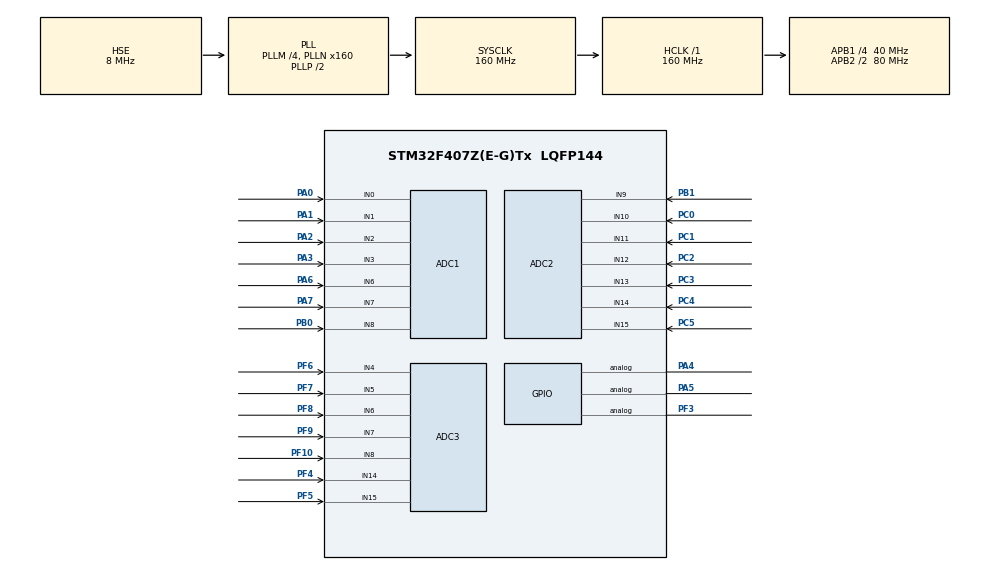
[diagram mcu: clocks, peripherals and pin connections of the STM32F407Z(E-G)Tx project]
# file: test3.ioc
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ADC1.Channel-0\#ChannelRegularConversion=ADC_CHANNEL_0
ADC1.NbrOfConversionFlag=1
ADC1.Rank-0\#ChannelRegularConversion=1
ADC1.SamplingTime-0\#ChannelRegularConversion=ADC_SAMPLETIME_3CYCLES
ADC1.master=1
ADC2.Channel-0\#ChannelRegularConversion=ADC_CHANNEL_9
ADC2.NbrOfConversionFlag=1
ADC2.Rank-0\#ChannelRegularConversion=1
ADC2.SamplingTime-0\#ChannelRegularConversion=ADC_SAMPLETIME_3CYCLES
ADC3.Channel-0\#ChannelRegularConversion=ADC_CHANNEL_4
ADC3.NbrOfConversionFlag=1
ADC3.Rank-0\#ChannelRegularConversion=1
ADC3.SamplingTime-0\#ChannelRegularConversion=ADC_SAMPLETIME_3CYCLES
FREERTOS.Tasks01=defaultTask,0,512,StartDefaultTask,Default,NULL,Dynamic,NULL,NULL
FREERTOS.configENABLE_BACKWARD_COMPATIBILITY=0
FREERTOS.configUSE_IDLE_HOOK=1
Mcu.Family=STM32F4
Mcu.Name=STM32F407Z(E-G)Tx
Mcu.Package=LQFP144
NVIC.PriorityGroup=NVIC_PRIORITYGROUP_4
NVIC.TIM6_DAC_IRQn=true\:0\:0\:false\:false\:true\:false\:false\:true
NVIC.TimeBase=TIM6_DAC_IRQn
NVIC.TimeBaseIP=TIM6
PA0-WKUP.Signal=ADCx_IN0
PA1.Signal=ADCx_IN1
PA13.Mode=Serial_Wire
PA13.Signal=SYS_JTMS-SWDIO
PA14.Mode=Serial_Wire
PA14.Signal=SYS_JTCK-SWCLK
PA2.Signal=ADCx_IN2
PA3.Signal=ADCx_IN3
PA4.Signal=GPIO_Analog
PA5.Signal=GPIO_Analog
PA6.Signal=ADCx_IN6
PA7.Signal=ADCx_IN7
PB0.Signal=ADCx_IN8
PB1.Signal=ADCx_IN9
PC0.Signal=ADCx_IN10
PC1.Signal=ADCx_IN11
PC14-OSC32_IN.Mode=LSE-External-Oscillator
PC14-OSC32_IN.Signal=RCC_OSC32_IN
PC15-OSC32_OUT.Mode=LSE-External-Oscillator
PC15-OSC32_OUT.Signal=RCC_OSC32_OUT
PC2.Signal=ADCx_IN12
PC3.Signal=ADCx_IN13
PC4.Signal=ADCx_IN14
PC5.Signal=ADCx_IN15
PF10.Mode=IN8
PF10.Signal=ADC3_IN8
PF3.Signal=GPIO_Analog
PF4.Mode=IN14
PF4.Signal=ADC3_IN14
PF5.Mode=IN15
PF5.Signal=ADC3_IN15
PF6.Mode=IN4
PF6.Signal=ADC3_IN4
PF7.Mode=IN5
PF7.Signal=ADC3_IN5
PF8.Mode=IN6
PF8.Signal=ADC3_IN6
PF9.Mode=IN7
PF9.Signal=ADC3_IN7
PH0-OSC_IN.Mode=HSE-External-Oscillator
PH0-OSC_IN.Signal=RCC_OSC_IN
PH1-OSC_OUT.Mode=HSE-External-Oscillator
PH1-OSC_OUT.Signal=RCC_OSC_OUT
ProjectManager.HeapSize=0x200
ProjectManager.StackSize=0x400
ProjectManager.TargetToolchain=Makefile
RCC.48MHZClocksFreq_Value=45714285.71428572
RCC.AHBFreq_Value=160000000
RCC.APB1CLKDivider=RCC_HCLK_DIV4
RCC.APB1Freq_Value=40000000
RCC.APB1TimFreq_Value=80000000
RCC.APB2CLKDivider=RCC_HCLK_DIV2
RCC.APB2Freq_Value=80000000
RCC.APB2TimFreq_Value=160000000
RCC.CortexFreq_Value=160000000
RCC.HCLKFreq_Value=160000000
RCC.HSE_VALUE=8000000
RCC.HSI_VALUE=16000000
RCC.PLLM=4
RCC.PLLN=160
RCC.PLLQ=7
RCC.PLLSourceVirtual=RCC_PLLSOURCE_HSE
RCC.RCC_RTC_Clock_Source=RCC_RTCCLKSOURCE_LSE
RCC.RCC_RTC_Clock_SourceVirtual=RCC_RTCCLKSOURCE_LSE
RCC.SYSCLKFreq_VALUE=160000000
RCC.SYSCLKSource=RCC_SYSCLKSOURCE_PLLCLK
RCC.VCOOutputFreq_Value=320000000
SH.ADCx_IN0.0=ADC1_IN0,IN0
SH.ADCx_IN1.0=ADC1_IN1,IN1
SH.ADCx_IN10.0=ADC2_IN10,IN10
SH.ADCx_IN11.0=ADC2_IN11,IN11
SH.ADCx_IN12.0=ADC2_IN12,IN12
SH.ADCx_IN13.0=ADC2_IN13,IN13
SH.ADCx_IN14.0=ADC2_IN14,IN14
SH.ADCx_IN15.0=ADC2_IN15,IN15
SH.ADCx_IN2.0=ADC1_IN2,IN2
SH.ADCx_IN3.0=ADC1_IN3,IN3
SH.ADCx_IN6.0=ADC1_IN6,IN6
SH.ADCx_IN7.0=ADC1_IN7,IN7
SH.ADCx_IN8.0=ADC1_IN8,IN8
SH.ADCx_IN9.0=ADC2_IN9,IN9
VP_FREERTOS_VS_CMSIS_V1.Mode=CMSIS_V1
VP_RTC_VS_RTC_Activate.Mode=RTC_Enabled
VP_SYS_VS_tim6.Mode=TIM6
board=custom

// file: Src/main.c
/* USER CODE BEGIN Header */
/**
  ******************************************************************************
  * @file           : main.c
  * @brief          : Main program body
  ******************************************************************************
  ** This notice applies to any and all portions of this file
  * that are not between comment pairs USER CODE BEGIN and
  * USER CODE END. Other portions of this file, whether
  * inserted by the user or by software development tools
  * are owned by their respective copyright owners.
  *
  * COPYRIGHT(c) 2018 STMicroelectronics
  *
  * Redistribution and use in source and binary forms, with or without modification,
  * are permitted provided that the following conditions are met:
  *   1. Redistributions of source code must retain the above copyright notice,
  *      this list of conditions and the following disclaimer.
  *   2. Redistributions in binary form must reproduce the above copyright notice,
  *      this list of conditions and the following disclaimer in the documentation
  *      and/or other materials provided with the distribution.
  *   3. Neither the name of STMicroelectronics nor the names of its contributors
  *      may be used to endorse or promote products derived from this software
  *      without specific prior written permission.
  *
  * THIS SOFTWARE IS PROVIDED BY THE COPYRIGHT HOLDERS AND CONTRIBUTORS "AS IS"
  * AND ANY EXPRESS OR IMPLIED WARRANTIES, INCLUDING, BUT NOT LIMITED TO, THE
  * IMPLIED WARRANTIES OF MERCHANTABILITY AND FITNESS FOR A PARTICULAR PURPOSE ARE
  * DISCLAIMED. IN NO EVENT SHALL THE COPYRIGHT HOLDER OR CONTRIBUTORS BE LIABLE
  * FOR ANY DIRECT, INDIRECT, INCIDENTAL, SPECIAL, EXEMPLARY, OR CONSEQUENTIAL
  * DAMAGES (INCLUDING, BUT NOT LIMITED TO, PROCUREMENT OF SUBSTITUTE GOODS OR
  * SERVICES; LOSS OF USE, DATA, OR PROFITS; OR BUSINESS INTERRUPTION) HOWEVER
  * CAUSED AND ON ANY THEORY OF LIABILITY, WHETHER IN CONTRACT, STRICT LIABILITY,
  * OR TORT (INCLUDING NEGLIGENCE OR OTHERWISE) ARISING IN ANY WAY OUT OF THE USE
  * OF THIS SOFTWARE, EVEN IF ADVISED OF THE POSSIBILITY OF SUCH DAMAGE.
  *
  ******************************************************************************
  */
/* USER CODE END Header */

#include "main.h"
#include "cmsis_os.h"

ADC_HandleTypeDef hadc1;
ADC_HandleTypeDef hadc2;
ADC_HandleTypeDef hadc3;

RTC_HandleTypeDef hrtc;

osThreadId defaultTaskHandle;

void SystemClock_Config(void);
static void MX_GPIO_Init(void);
static void MX_RTC_Init(void);
static void MX_ADC3_Init(void);
static void MX_ADC1_Init(void);
static void MX_ADC2_Init(void);
void StartDefaultTask(void const * argument);

int main(void)
{

  /* MCU Configuration--------------------------------------------------------*/

  /* Reset of all peripherals, Initializes the Flash interface and the Systick. */
  HAL_Init();

  /* Configure the system clock */
  SystemClock_Config();

  /* Initialize all configured peripherals */
  MX_GPIO_Init();
  MX_RTC_Init();
  MX_ADC3_Init();
  MX_ADC1_Init();
  MX_ADC2_Init();

  /* Create the thread(s) */
  /* definition and creation of defaultTask */
  osThreadDef(defaultTask, StartDefaultTask, osPriorityNormal, 0, 512);
  defaultTaskHandle = osThreadCreate(osThread(defaultTask), NULL);

  /* Start scheduler */
  osKernelStart();

  /* We should never get here as control is now taken by the scheduler */

  /* Infinite loop */
  while (1)
  {

  }
}

void SystemClock_Config(void)
{
  RCC_OscInitTypeDef RCC_OscInitStruct = {0};
  RCC_ClkInitTypeDef RCC_ClkInitStruct = {0};
  RCC_PeriphCLKInitTypeDef PeriphClkInitStruct = {0};

  /** Configure the main internal regulator output voltage
  */
  __HAL_RCC_PWR_CLK_ENABLE();
  __HAL_PWR_VOLTAGESCALING_CONFIG(PWR_REGULATOR_VOLTAGE_SCALE1);
  /** Initializes the CPU, AHB and APB busses clocks
  */
  RCC_OscInitStruct.OscillatorType = RCC_OSCILLATORTYPE_HSE|RCC_OSCILLATORTYPE_LSE;
  RCC_OscInitStruct.HSEState = RCC_HSE_ON;
  RCC_OscInitStruct.LSEState = RCC_LSE_ON;
  RCC_OscInitStruct.PLL.PLLState = RCC_PLL_ON;
  RCC_OscInitStruct.PLL.PLLSource = RCC_PLLSOURCE_HSE;
  RCC_OscInitStruct.PLL.PLLM = 4;
  RCC_OscInitStruct.PLL.PLLN = 160;
  RCC_OscInitStruct.PLL.PLLP = RCC_PLLP_DIV2;
  RCC_OscInitStruct.PLL.PLLQ = 7;
  if (HAL_RCC_OscConfig(&RCC_OscInitStruct) != HAL_OK)
  {
    Error_Handler();
  }
  /** Initializes the CPU, AHB and APB busses clocks
  */
  RCC_ClkInitStruct.ClockType = RCC_CLOCKTYPE_HCLK|RCC_CLOCKTYPE_SYSCLK
                              |RCC_CLOCKTYPE_PCLK1|RCC_CLOCKTYPE_PCLK2;
  RCC_ClkInitStruct.SYSCLKSource = RCC_SYSCLKSOURCE_PLLCLK;
  RCC_ClkInitStruct.AHBCLKDivider = RCC_SYSCLK_DIV1;
  RCC_ClkInitStruct.APB1CLKDivider = RCC_HCLK_DIV4;
  RCC_ClkInitStruct.APB2CLKDivider = RCC_HCLK_DIV2;

  if (HAL_RCC_ClockConfig(&RCC_ClkInitStruct, FLASH_LATENCY_5) != HAL_OK)
  {
    Error_Handler();
  }
  PeriphClkInitStruct.PeriphClockSelection = RCC_PERIPHCLK_RTC;
  PeriphClkInitStruct.RTCClockSelection = RCC_RTCCLKSOURCE_LSE;
  if (HAL_RCCEx_PeriphCLKConfig(&PeriphClkInitStruct) != HAL_OK)
  {
    Error_Handler();
  }
}

static void MX_ADC1_Init(void)
{

  ADC_ChannelConfTypeDef sConfig = {0};

  /** Configure the global features of the ADC (Clock, Resolution, Data Alignment and number of conversion)
  */
  hadc1.Instance = ADC1;
  hadc1.Init.ClockPrescaler = ADC_CLOCK_SYNC_PCLK_DIV4;
  hadc1.Init.Resolution = ADC_RESOLUTION_12B;
  hadc1.Init.ScanConvMode = DISABLE;
  hadc1.Init.ContinuousConvMode = DISABLE;
  hadc1.Init.DiscontinuousConvMode = DISABLE;
  hadc1.Init.ExternalTrigConvEdge = ADC_EXTERNALTRIGCONVEDGE_NONE;
  hadc1.Init.ExternalTrigConv = ADC_SOFTWARE_START;
  hadc1.Init.DataAlign = ADC_DATAALIGN_RIGHT;
  hadc1.Init.NbrOfConversion = 1;
  hadc1.Init.DMAContinuousRequests = DISABLE;
  hadc1.Init.EOCSelection = ADC_EOC_SINGLE_CONV;
  if (HAL_ADC_Init(&hadc1) != HAL_OK)
  {
    Error_Handler();
  }
  /** Configure for the selected ADC regular channel its corresponding rank in the sequencer and its sample time.
  */
  sConfig.Channel = ADC_CHANNEL_0;
  sConfig.Rank = 1;
  sConfig.SamplingTime = ADC_SAMPLETIME_3CYCLES;
  if (HAL_ADC_ConfigChannel(&hadc1, &sConfig) != HAL_OK)
  {
    Error_Handler();
  }

}

static void MX_ADC2_Init(void)
{

  ADC_ChannelConfTypeDef sConfig = {0};

  /** Configure the global features of the ADC (Clock, Resolution, Data Alignment and number of conversion)
  */
  hadc2.Instance = ADC2;
  hadc2.Init.ClockPrescaler = ADC_CLOCK_SYNC_PCLK_DIV4;
  hadc2.Init.Resolution = ADC_RESOLUTION_12B;
  hadc2.Init.ScanConvMode = DISABLE;
  hadc2.Init.ContinuousConvMode = DISABLE;
  hadc2.Init.DiscontinuousConvMode = DISABLE;
  hadc2.Init.ExternalTrigConvEdge = ADC_EXTERNALTRIGCONVEDGE_NONE;
  hadc2.Init.ExternalTrigConv = ADC_SOFTWARE_START;
  hadc2.Init.DataAlign = ADC_DATAALIGN_RIGHT;
  hadc2.Init.NbrOfConversion = 1;
  hadc2.Init.DMAContinuousRequests = DISABLE;
  hadc2.Init.EOCSelection = ADC_EOC_SINGLE_CONV;
  if (HAL_ADC_Init(&hadc2) != HAL_OK)
  {
    Error_Handler();
  }
  /** Configure for the selected ADC regular channel its corresponding rank in the sequencer and its sample time.
  */
  sConfig.Channel = ADC_CHANNEL_9;
  sConfig.Rank = 1;
  sConfig.SamplingTime = ADC_SAMPLETIME_3CYCLES;
  if (HAL_ADC_ConfigChannel(&hadc2, &sConfig) != HAL_OK)
  {
    Error_Handler();
  }

}

static void MX_ADC3_Init(void)
{

  ADC_ChannelConfTypeDef sConfig = {0};

  /** Configure the global features of the ADC (Clock, Resolution, Data Alignment and number of conversion)
  */
  hadc3.Instance = ADC3;
  hadc3.Init.ClockPrescaler = ADC_CLOCK_SYNC_PCLK_DIV4;
  hadc3.Init.Resolution = ADC_RESOLUTION_12B;
  hadc3.Init.ScanConvMode = DISABLE;
  hadc3.Init.ContinuousConvMode = DISABLE;
  hadc3.Init.DiscontinuousConvMode = DISABLE;
  hadc3.Init.ExternalTrigConvEdge = ADC_EXTERNALTRIGCONVEDGE_NONE;
  hadc3.Init.ExternalTrigConv = ADC_SOFTWARE_START;
  hadc3.Init.DataAlign = ADC_DATAALIGN_RIGHT;
  hadc3.Init.NbrOfConversion = 1;
  hadc3.Init.DMAContinuousRequests = DISABLE;
  hadc3.Init.EOCSelection = ADC_EOC_SINGLE_CONV;
  if (HAL_ADC_Init(&hadc3) != HAL_OK)
  {
    Error_Handler();
  }
  /** Configure for the selected ADC regular channel its corresponding rank in the sequencer and its sample time.
  */
  sConfig.Channel = ADC_CHANNEL_4;
  sConfig.Rank = 1;
  sConfig.SamplingTime = ADC_SAMPLETIME_3CYCLES;
  if (HAL_ADC_ConfigChannel(&hadc3, &sConfig) != HAL_OK)
  {
    Error_Handler();
  }

}

static void MX_RTC_Init(void)
{

  /** Initialize RTC Only
  */
  hrtc.Instance = RTC;
  hrtc.Init.HourFormat = RTC_HOURFORMAT_24;
  hrtc.Init.AsynchPrediv = 127;
  hrtc.Init.SynchPrediv = 255;
  hrtc.Init.OutPut = RTC_OUTPUT_DISABLE;
  hrtc.Init.OutPutPolarity = RTC_OUTPUT_POLARITY_HIGH;
  hrtc.Init.OutPutType = RTC_OUTPUT_TYPE_OPENDRAIN;
  if (HAL_RTC_Init(&hrtc) != HAL_OK)
  {
    Error_Handler();
  }

}

static void MX_GPIO_Init(void)
{
  GPIO_InitTypeDef GPIO_InitStruct = {0};

  /* GPIO Ports Clock Enable */
  __HAL_RCC_GPIOC_CLK_ENABLE();
  __HAL_RCC_GPIOF_CLK_ENABLE();
  __HAL_RCC_GPIOH_CLK_ENABLE();
  __HAL_RCC_GPIOA_CLK_ENABLE();
  __HAL_RCC_GPIOB_CLK_ENABLE();

  /*Configure GPIO pin : PF3 */
  GPIO_InitStruct.Pin = GPIO_PIN_3;
  GPIO_InitStruct.Mode = GPIO_MODE_ANALOG;
  GPIO_InitStruct.Pull = GPIO_NOPULL;
  HAL_GPIO_Init(GPIOF, &GPIO_InitStruct);

  /*Configure GPIO pins : PA4 PA5 */
  GPIO_InitStruct.Pin = GPIO_PIN_4|GPIO_PIN_5;
  GPIO_InitStruct.Mode = GPIO_MODE_ANALOG;
  GPIO_InitStruct.Pull = GPIO_NOPULL;
  HAL_GPIO_Init(GPIOA, &GPIO_InitStruct);

}

void StartDefaultTask(void const * argument)
{
  /* USER CODE BEGIN 5 */
  extern void maintask();
  maintask();

  /* Infinite loop */
  for(;;)
  {
    osDelay(1);
  }
  /* USER CODE END 5 */
}

void HAL_TIM_PeriodElapsedCallback(TIM_HandleTypeDef *htim)
{
  if (htim->Instance == TIM6) {
    HAL_IncTick();
  }
}

void Error_Handler(void)
{
}

/************************ (C) COPYRIGHT STMicroelectronics *****END OF FILE****/
